VERSION ""

NS_ :

BS_:

BU_: BMS

BO_ 293 BMS_VC: 8 Vector__XXX

BO_ 1767 Module_1_Voltage: 8 BMS
 SG_ Cell_Voltage_4 : 55|16@0+ (1,0) [0|0] "mV" Vector__XXX
 SG_ Cell_Voltage_3 : 39|16@0+ (1,0) [0|0] "mV" Vector__XXX
 SG_ Cell_Voltage_2 : 23|16@0+ (1,0) [0|0] "mV" Vector__XXX
 SG_ Cell_Voltage_1 : 7|16@0+ (1,0) [0|0] "mV" Vector__XXX

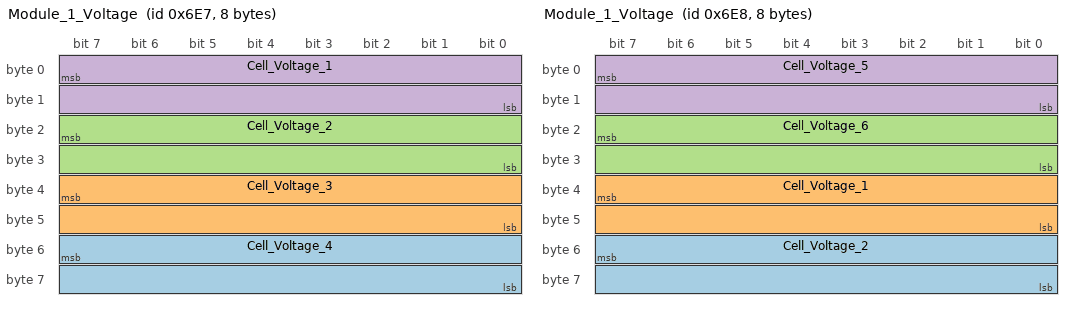
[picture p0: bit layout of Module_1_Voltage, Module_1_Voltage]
BO_ 1768 Module_1_Voltage: 8 BMS
 SG_ Cell_Voltage_2 : 55|16@0+ (1,0) [0|0] "mV" Vector__XXX
 SG_ Cell_Voltage_1 : 39|16@0+ (1,0) [0|0] "mV" Vector__XXX
 SG_ Cell_Voltage_6 : 23|16@0+ (1,0) [0|0] "mV" Vector__XXX
 SG_ Cell_Voltage_5 : 7|16@0+ (1,0) [0|0] "mV" Vector__XXX

BO_ 1769 Module_Voltage: 8 BMS
 SG_ Cell_Voltage_4 : 55|16@0+ (1,0) [0|0] "mV" Vector__XXX
 SG_ Cell_Voltage_3 : 39|16@0+ (1,0) [0|0] "mV" Vector__XXX
 SG_ Cell_Voltage_2 : 23|16@0+ (1,0) [0|0] "mV" Vector__XXX
 SG_ Cell_Voltage_1 : 7|16@0+ (1,0) [0|0] "mV" Vector__XXX

BO_ 1771 Module_Voltage: 8 BMS
 SG_ Cell_Voltage_4 : 55|16@0+ (1,0) [0|0] "mV" Vector__XXX
 SG_ Cell_Voltage_3 : 39|16@0+ (1,0) [0|0] "mV" Vector__XXX
 SG_ Cell_Voltage_2 : 23|16@0+ (1,0) [0|0] "mV" Vector__XXX
 SG_ Cell_Voltage_1 : 7|16@0+ (1,0) [0|0] "mV" Vector__XXX

BO_ 1772 Module_Voltage: 8 BMS
 SG_ Cell_Voltage_4 : 55|16@0+ (1,0) [0|0] "mV" Vector__XXX
 SG_ Cell_Voltage_3 : 39|16@0+ (1,0) [0|0] "mV" Vector__XXX
 SG_ Cell_Voltage_2 : 23|16@0+ (1,0) [0|0] "mV" Vector__XXX
 SG_ Cell_Voltage_1 : 7|16@0+ (1,0) [0|0] "mV" Vector__XXX

BO_ 1773 Module_Voltage: 8 BMS
 SG_ Cell_Voltage_4 : 55|16@0+ (1,0) [0|0] "mV" Vector__XXX
 SG_ Cell_Voltage_3 : 39|16@0+ (1,0) [0|0] "mV" Vector__XXX
 SG_ Cell_Voltage_2 : 23|16@0+ (1,0) [0|0] "mV" Vector__XXX
 SG_ Cell_Voltage_1 : 7|16@0+ (1,0) [0|0] "mV" Vector__XXX

BO_ 1774 Module_Voltage: 8 BMS
 SG_ Cell_Voltage_4 : 55|16@0+ (1,0) [0|0] "mV" Vector__XXX
 SG_ Cell_Voltage_3 : 39|16@0+ (1,0) [0|0] "mV" Vector__XXX
 SG_ Cell_Voltage_2 : 23|16@0+ (1,0) [0|0] "mV" Vector__XXX
 SG_ Cell_Voltage_1 : 7|16@0+ (1,0) [0|0] "mV" Vector__XXX

BO_ 1775 Module_Voltage: 8 BMS
 SG_ Cell_Voltage_4 : 55|16@0+ (1,0) [0|0] "mV" Vector__XXX
 SG_ Cell_Voltage_3 : 39|16@0+ (1,0) [0|0] "mV" Vector__XXX
 SG_ Cell_Voltage_2 : 23|16@0+ (1,0) [0|0] "mV" Vector__XXX
 SG_ Cell_Voltage_1 : 7|16@0+ (1,0) [0|0] "mV" Vector__XXX

BO_ 1776 Module_Voltage: 8 BMS
 SG_ Cell_Voltage_4 : 55|16@0+ (1,0) [0|0] "mV" Vector__XXX
 SG_ Cell_Voltage_3 : 39|16@0+ (1,0) [0|0] "mV" Vector__XXX
 SG_ Cell_Voltage_2 : 23|16@0+ (1,0) [0|0] "mV" Vector__XXX
 SG_ Cell_Voltage_1 : 7|16@0+ (1,0) [0|0] "mV" Vector__XXX

BO_ 1777 Module_Voltage: 8 BMS
 SG_ Cell_Voltage_4 : 55|16@0+ (1,0) [0|0] "mV" Vector__XXX
 SG_ Cell_Voltage_3 : 39|16@0+ (1,0) [0|0] "mV" Vector__XXX
 SG_ Cell_Voltage_2 : 23|16@0+ (1,0) [0|0] "mV" Vector__XXX
 SG_ Cell_Voltage_1 : 7|16@0+ (1,0) [0|0] "mV" Vector__XXX

BO_ 1778 Module_Voltage: 8 BMS
 SG_ Cell_Voltage_4 : 55|16@0+ (1,0) [0|0] "mV" Vector__XXX
 SG_ Cell_Voltage_3 : 39|16@0+ (1,0) [0|0] "mV" Vector__XXX
 SG_ Cell_Voltage_2 : 23|16@0+ (1,0) [0|0] "mV" Vector__XXX
 SG_ Cell_Voltage_1 : 7|16@0+ (1,0) [0|0] "mV" Vector__XXX

BO_ 1779 Module_Voltage: 8 BMS
 SG_ Cell_Voltage_4 : 55|16@0+ (1,0) [0|0] "mV" Vector__XXX
 SG_ Cell_Voltage_3 : 39|16@0+ (1,0) [0|0] "mV" Vector__XXX
 SG_ Cell_Voltage_2 : 23|16@0+ (1,0) [0|0] "mV" Vector__XXX
 SG_ Cell_Voltage_1 : 7|16@0+ (1,0) [0|0] "mV" Vector__XXX

BO_ 1780 Module_Voltage: 8 BMS
 SG_ Cell_Voltage_4 : 55|16@0+ (1,0) [0|0] "mV" Vector__XXX
 SG_ Cell_Voltage_3 : 39|16@0+ (1,0) [0|0] "mV" Vector__XXX
 SG_ Cell_Voltage_2 : 23|16@0+ (1,0) [0|0] "mV" Vector__XXX
 SG_ Cell_Voltage_1 : 7|16@0+ (1,0) [0|0] "mV" Vector__XXX

BO_ 1781 Module_Voltage: 8 BMS
 SG_ Cell_Voltage_4 : 55|16@0+ (1,0) [0|0] "mV" Vector__XXX
 SG_ Cell_Voltage_3 : 39|16@0+ (1,0) [0|0] "mV" Vector__XXX
 SG_ Cell_Voltage_2 : 23|16@0+ (1,0) [0|0] "mV" Vector__XXX
 SG_ Cell_Voltage_1 : 7|16@0+ (1,0) [0|0] "mV" Vector__XXX

BO_ 1782 Module_Voltage: 8 BMS
 SG_ Cell_Voltage_4 : 55|16@0+ (1,0) [0|0] "mV" Vector__XXX
 SG_ Cell_Voltage_3 : 39|16@0+ (1,0) [0|0] "mV" Vector__XXX
 SG_ Cell_Voltage_2 : 23|16@0+ (1,0) [0|0] "mV" Vector__XXX
 SG_ Cell_Voltage_1 : 7|16@0+ (1,0) [0|0] "mV" Vector__XXX

BO_ 1783 Module_Voltage: 8 BMS
 SG_ Cell_Voltage_4 : 55|16@0+ (1,0) [0|0] "mV" Vector__XXX
 SG_ Cell_Voltage_3 : 39|16@0+ (1,0) [0|0] "mV" Vector__XXX
 SG_ Cell_Voltage_2 : 23|16@0+ (1,0) [0|0] "mV" Vector__XXX
 SG_ Cell_Voltage_1 : 7|16@0+ (1,0) [0|0] "mV" Vector__XXX

BO_ 1784 Module_Voltage: 8 BMS
 SG_ Cell_Voltage_4 : 55|16@0+ (1,0) [0|0] "mV" Vector__XXX
 SG_ Cell_Voltage_3 : 39|16@0+ (1,0) [0|0] "mV" Vector__XXX
 SG_ Cell_Voltage_2 : 23|16@0+ (1,0) [0|0] "mV" Vector__XXX
 SG_ Cell_Voltage_1 : 7|16@0+ (1,0) [0|0] "mV" Vector__XXX

BO_ 1785 Module_Voltage: 8 BMS
 SG_ Cell_Voltage_4 : 55|16@0+ (1,0) [0|0] "mV" Vector__XXX
 SG_ Cell_Voltage_3 : 39|16@0+ (1,0) [0|0] "mV" Vector__XXX
 SG_ Cell_Voltage_2 : 23|16@0+ (1,0) [0|0] "mV" Vector__XXX
 SG_ Cell_Voltage_1 : 7|16@0+ (1,0) [0|0] "mV" Vector__XXX

BO_ 1786 Module_Voltage: 8 BMS
 SG_ Cell_Voltage_4 : 55|16@0+ (1,0) [0|0] "mV" Vector__XXX
 SG_ Cell_Voltage_3 : 39|16@0+ (1,0) [0|0] "mV" Vector__XXX
 SG_ Cell_Voltage_2 : 23|16@0+ (1,0) [0|0] "mV" Vector__XXX
 SG_ Cell_Voltage_1 : 7|16@0+ (1,0) [0|0] "mV" Vector__XXX

BO_ 1787 Module_Voltage: 8 BMS
 SG_ Cell_Voltage_4 : 55|16@0+ (1,0) [0|0] "mV" Vector__XXX
 SG_ Cell_Voltage_3 : 39|16@0+ (1,0) [0|0] "mV" Vector__XXX
 SG_ Cell_Voltage_2 : 23|16@0+ (1,0) [0|0] "mV" Vector__XXX
 SG_ Cell_Voltage_1 : 7|16@0+ (1,0) [0|0] "mV" Vector__XXX

BO_ 1788 Module_Voltage: 8 BMS
 SG_ Cell_Voltage_4 : 55|16@0+ (1,0) [0|0] "mV" Vector__XXX
 SG_ Cell_Voltage_3 : 39|16@0+ (1,0) [0|0] "mV" Vector__XXX
 SG_ Cell_Voltage_2 : 23|16@0+ (1,0) [0|0] "mV" Vector__XXX
 SG_ Cell_Voltage_1 : 7|16@0+ (1,0) [0|0] "mV" Vector__XXX

BO_ 1789 Module_Voltage: 8 BMS
 SG_ Cell_Voltage_4 : 55|16@0+ (1,0) [0|0] "mV" Vector__XXX
 SG_ Cell_Voltage_3 : 39|16@0+ (1,0) [0|0] "mV" Vector__XXX
 SG_ Cell_Voltage_2 : 23|16@0+ (1,0) [0|0] "mV" Vector__XXX
 SG_ Cell_Voltage_1 : 7|16@0+ (1,0) [0|0] "mV" Vector__XXX

BO_ 1790 Module_Voltage: 8 BMS
 SG_ Cell_Voltage_4 : 55|16@0+ (1,0) [0|0] "mV" Vector__XXX
 SG_ Cell_Voltage_3 : 39|16@0+ (1,0) [0|0] "mV" Vector__XXX
 SG_ Cell_Voltage_2 : 23|16@0+ (1,0) [0|0] "mV" Vector__XXX
 SG_ Cell_Voltage_1 : 7|16@0+ (1,0) [0|0] "mV" Vector__XXX

BO_ 1791 Module_Voltage: 8 BMS
 SG_ Cell_Voltage_4 : 55|16@0+ (1,0) [0|0] "mV" Vector__XXX
 SG_ Cell_Voltage_3 : 39|16@0+ (1,0) [0|0] "mV" Vector__XXX
 SG_ Cell_Voltage_2 : 23|16@0+ (1,0) [0|0] "mV" Vector__XXX
 SG_ Cell_Voltage_1 : 7|16@0+ (1,0) [0|0] "mV" Vector__XXX

BO_ 1761 Module_Voltage: 8 BMS
 SG_ Cell_Voltage_4 : 55|16@0+ (1,0) [0|0] "mV" Vector__XXX
 SG_ Cell_Voltage_3 : 39|16@0+ (1,0) [0|0] "mV" Vector__XXX
 SG_ Cell_Voltage_2 : 23|16@0+ (1,0) [0|0] "mV" Vector__XXX
 SG_ Cell_Voltage_1 : 7|16@0+ (1,0) [0|0] "mV" Vector__XXX

BO_ 1762 Module_Voltage: 8 BMS
 SG_ Cell_Voltage_4 : 55|16@0+ (1,0) [0|0] "mV" Vector__XXX
 SG_ Cell_Voltage_3 : 39|16@0+ (1,0) [0|0] "mV" Vector__XXX
 SG_ Cell_Voltage_2 : 23|16@0+ (1,0) [0|0] "mV" Vector__XXX
 SG_ Cell_Voltage_1 : 7|16@0+ (1,0) [0|0] "mV" Vector__XXX

BO_ 1747 Module_Voltage: 8 BMS
 SG_ Cell_Voltage_4 : 55|16@0+ (1,0) [0|0] "mV" Vector__XXX
 SG_ Cell_Voltage_3 : 39|16@0+ (1,0) [0|0] "mV" Vector__XXX
 SG_ Cell_Voltage_2 : 23|16@0+ (1,0) [0|0] "mV" Vector__XXX
 SG_ Cell_Voltage_1 : 7|16@0+ (1,0) [0|0] "mV" Vector__XXX

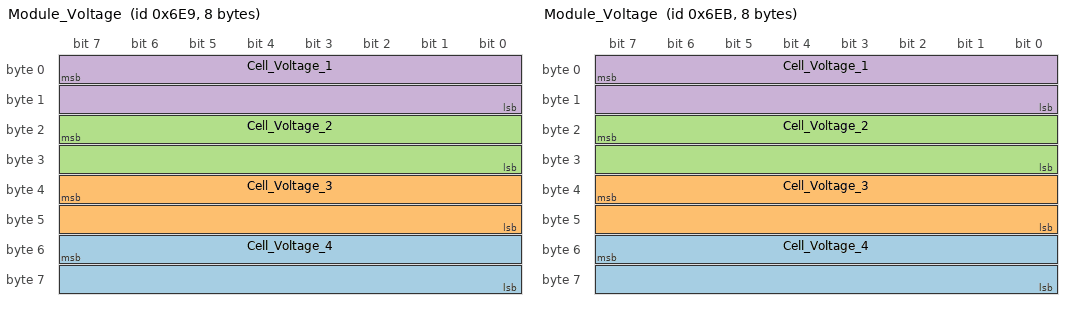
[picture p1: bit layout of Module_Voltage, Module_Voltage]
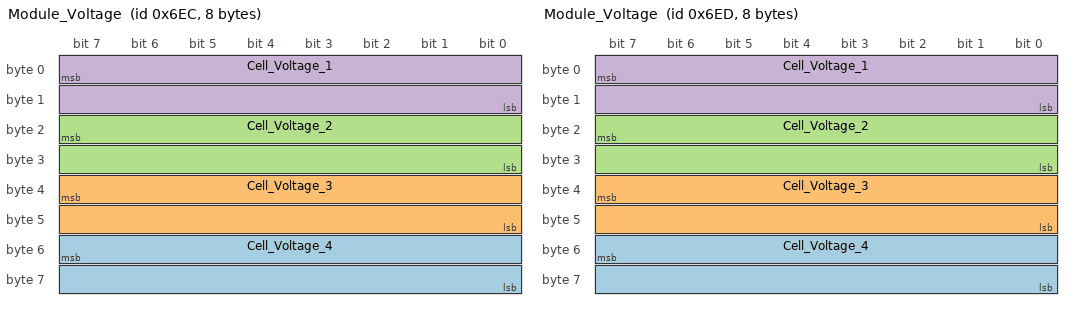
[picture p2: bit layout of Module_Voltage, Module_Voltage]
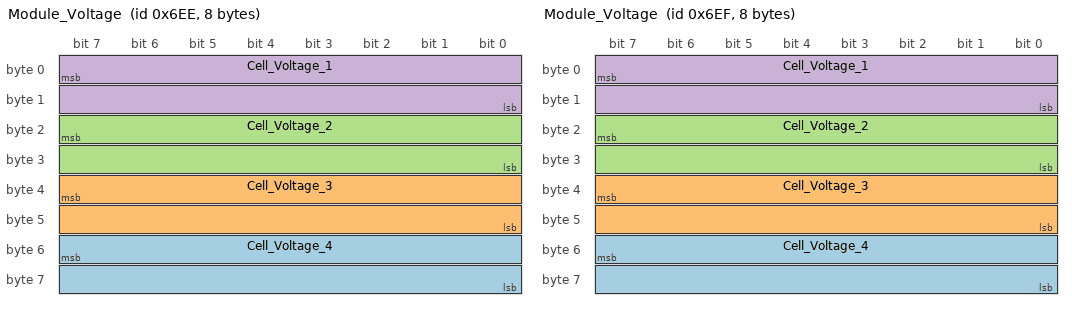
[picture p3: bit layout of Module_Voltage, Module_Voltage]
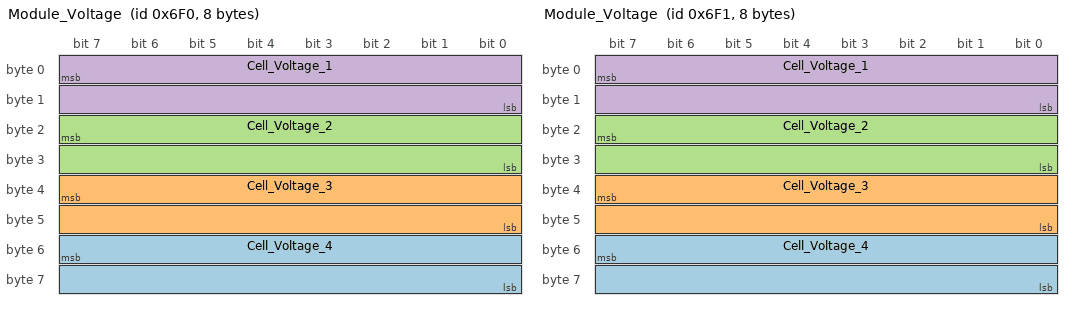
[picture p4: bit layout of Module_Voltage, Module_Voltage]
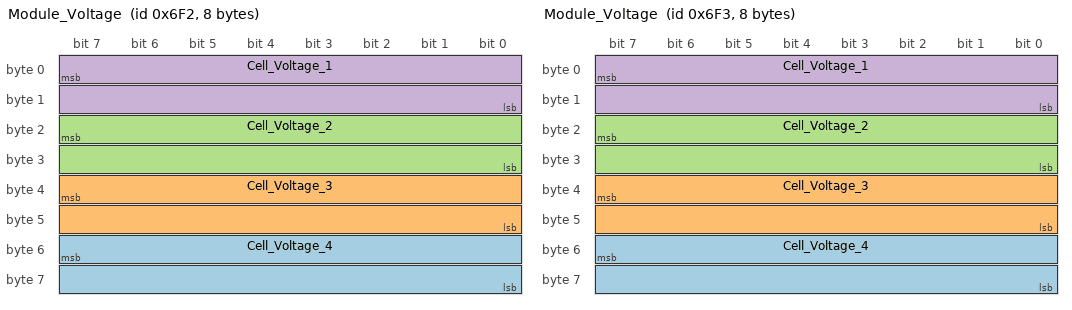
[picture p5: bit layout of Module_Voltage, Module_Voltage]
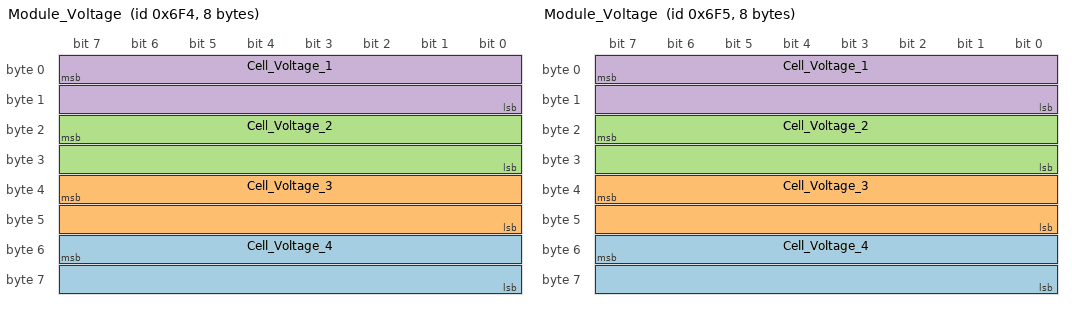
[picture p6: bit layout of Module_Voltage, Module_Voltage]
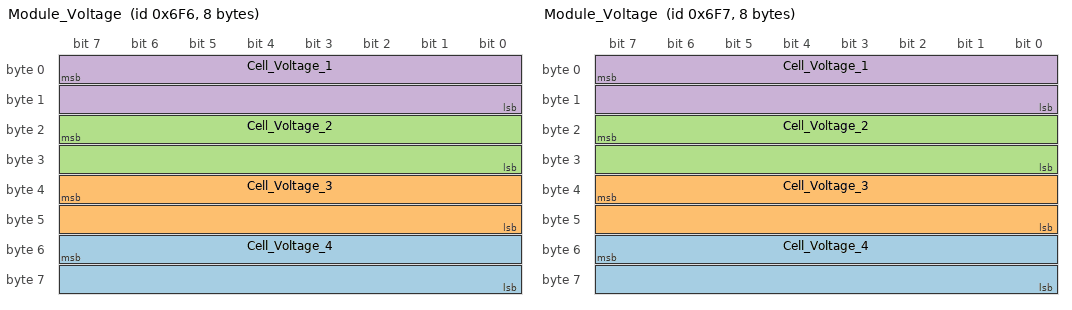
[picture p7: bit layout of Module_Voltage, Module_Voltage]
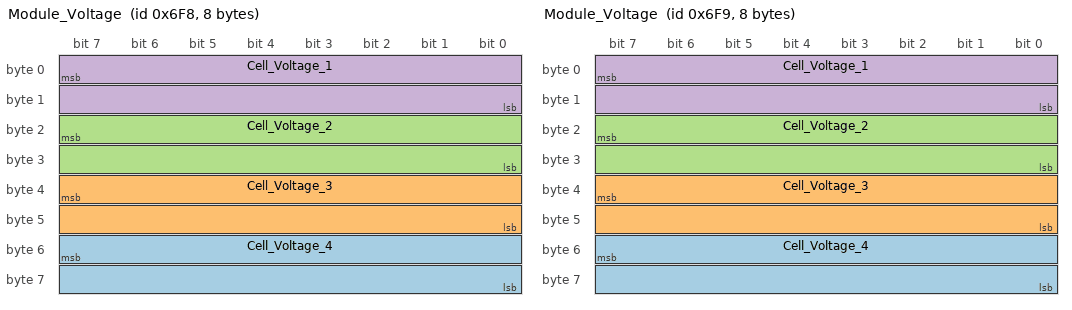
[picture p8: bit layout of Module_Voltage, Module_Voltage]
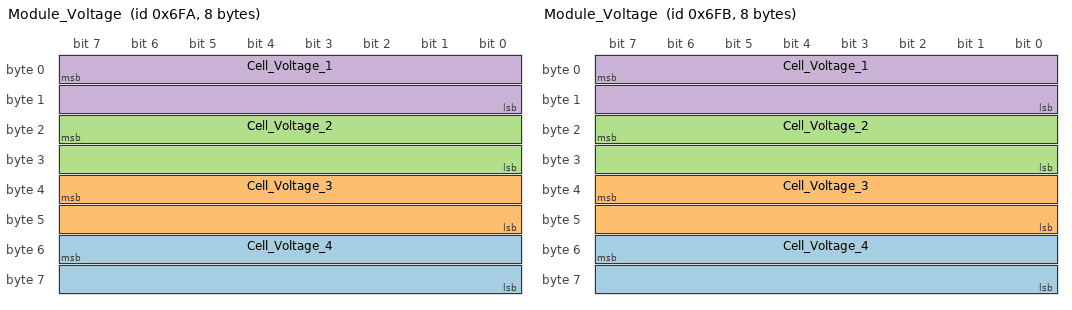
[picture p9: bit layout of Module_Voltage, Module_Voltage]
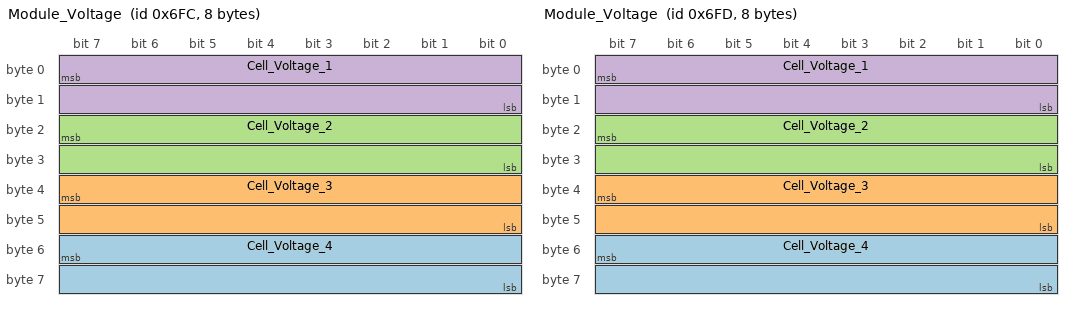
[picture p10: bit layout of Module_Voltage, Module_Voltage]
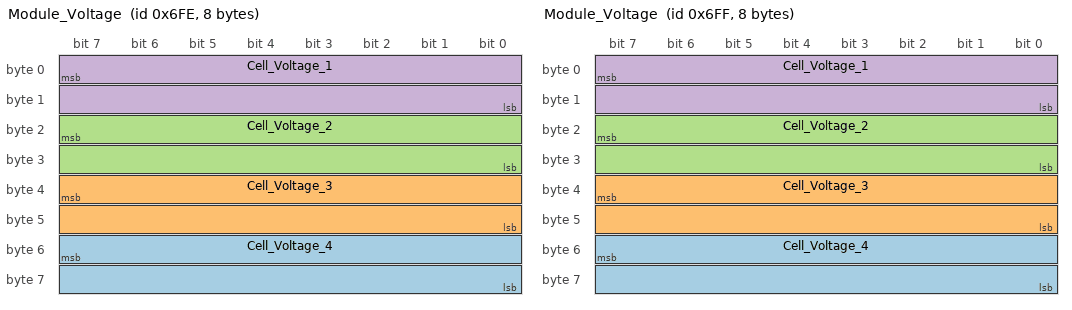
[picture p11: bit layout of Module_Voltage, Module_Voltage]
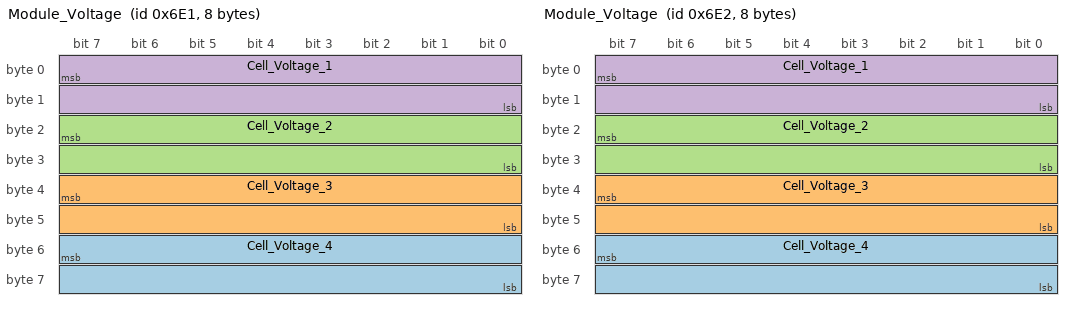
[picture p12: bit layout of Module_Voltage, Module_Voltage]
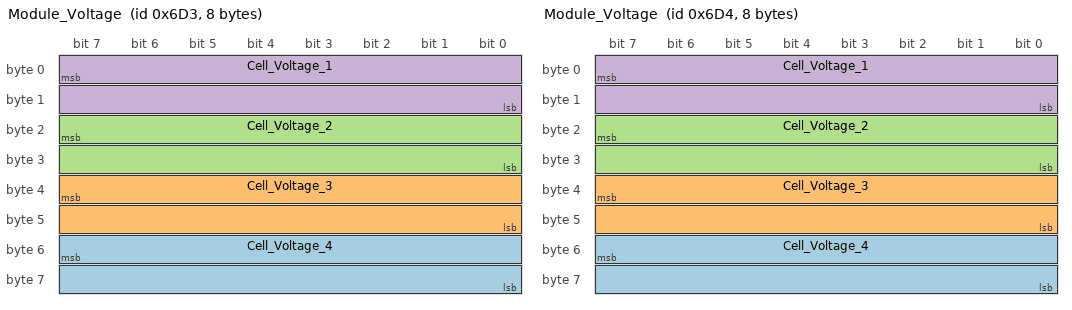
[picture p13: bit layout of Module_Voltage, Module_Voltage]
BO_ 1748 Module_Voltage: 8 BMS
 SG_ Cell_Voltage_4 : 55|16@0+ (1,0) [0|0] "mV" Vector__XXX
 SG_ Cell_Voltage_3 : 39|16@0+ (1,0) [0|0] "mV" Vector__XXX
 SG_ Cell_Voltage_2 : 23|16@0+ (1,0) [0|0] "mV" Vector__XXX
 SG_ Cell_Voltage_1 : 7|16@0+ (1,0) [0|0] "mV" Vector__XXX

BA_DEF_  "BusType" STRING ;
BA_DEF_DEF_  "BusType" "CAN";
